# MCXN947_cm33_core0 register map
Vendor: nxp.com; File version: 1.0
CPU: CM33 r2p0, little endian, MPU, FPU, VTOR, 3 interrupt priority bits
Registers are 32-bit, read-write, reset 0x0 unless marked. A register's access mark holds for its fields unless they carry their own. Offsets are from the block's base; [hi:lo] are bit positions; lines under a group give offsets from that group; {n}, {i} and the like mark numbered series; 'fields as' and 'values as' point back to an identical list.

## INTM0 — INTM
Base 0x4005D000
0x00 INTM_MM — Monitor Mode
  [0] MM
    0=disable; 1=enable
0x04 INTM_IACK wo — Interrupt Acknowledge
  [9:0] IRQ — Interrupt Request
{0x8+0x10*i} mon[{i}] (i=0..3) group — Monitoring
  0x00 INTM_IRQSEL — Interrupt Request Select for Monitor mon_index
    [9:0] IRQ — Interrupt Request
  0x04 INTM_LATENCY — Interrupt Latency for Monitor mon_index
    [23:0] LAT — Latency
  0x08 INTM_TIMER — Timer for Monitor mon_index
    [23:0] TIMER
  0x0C INTM_STATUS ro — Status for Monitor mon_index
    [0] STATUS — Monitor status
      0=ST02 (Did not exceed); 1=ST01 (Exceeded)

## LP_FLEXCOMM0 — LP_FLEXCOMM
Base 0x40092000; alternate view of LPSPI0
Same registers: LP_FLEXCOMM1 0x40093000 (alternate view of LPSPI1), LP_FLEXCOMM2 0x40094000 (alternate view of LPSPI2), LP_FLEXCOMM3 0x40095000 (alternate view of LPSPI3), LP_FLEXCOMM4 0x400B4000 (alternate view of LPSPI4), LP_FLEXCOMM5 0x400B5000 (alternate view of LPSPI5), LP_FLEXCOMM6 0x400B6000 (alternate view of LPSPI6), LP_FLEXCOMM7 0x400B7000 (alternate view of LPSPI7), LP_FLEXCOMM8 0x400B8000 (alternate view of LPSPI8), LP_FLEXCOMM9 0x400B9000 (alternate view of LPSPI9)
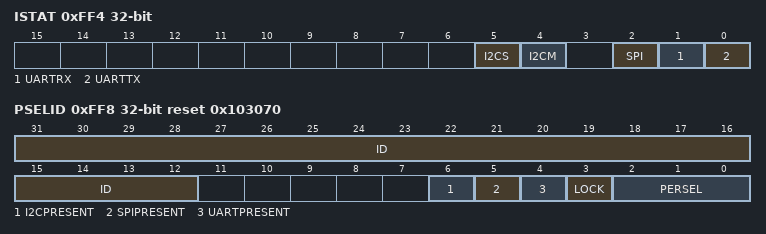
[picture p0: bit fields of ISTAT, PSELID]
0xFF4 ISTAT ro — Interrupt Status
  [all] fields
    0=CLR (Clear); 1=SET
  [5] I2CS — I2C Subordinate Interrupt
  [4] I2CM — I2C Controller Interrupt
  [2] SPI — SPI Interrupt
  [1] UARTRX — UART RX Interrupt
  [0] UARTTX — UART TX Interrupt
0xFF8 PSELID reset 0x103070 — Peripheral Select and ID
  [31:12] ID ro — LP_FLEXCOMM interface ID
  [6] I2CPRESENT ro
    0=FALSE (Not supported); 1=TRUE (Supported)
  [5] SPIPRESENT ro
    0=FALSE (Not supported); 1=TRUE (Supported)
  [4] UARTPRESENT ro
    0=FALSE (Not supported); 1=TRUE (Supported)
  [3] LOCK
    0=FALSE (PERSEL is writable); 1=TRUE (PERSEL is not writable)
  [2:0] PERSEL — Peripheral Select
    0=NONE (No peripheral selected); 1=UART; 2=SPI; 3=I2C; 7=UARTI2C (UART and I2C)

## SEMA42_0 — SEMA42
Base 0x400B1000
0x00 GATE3 8-bit — Gate
  [3:0] GTFSM — Gate Finite State Machine
    0=UNLOCKED (The gate is unlocked (free).); {v}=LOCKED_BY_D{v-1} (Domain {v-1} locked the gate.) (v=1..15)
0x01 GATE2 8-bit — Gate
  fields as GATE3
0x02 GATE1 8-bit — Gate
  fields as GATE3
0x03 GATE0 8-bit — Gate
  fields as GATE3
0x04 GATE7 8-bit — Gate
  fields as GATE3
0x05 GATE6 8-bit — Gate
  fields as GATE3
0x06 GATE5 8-bit — Gate
  fields as GATE3
0x07 GATE4 8-bit — Gate
  fields as GATE3
0x08 GATE11 8-bit — Gate
  fields as GATE3
0x09 GATE10 8-bit — Gate
  fields as GATE3
0x0A GATE9 8-bit — Gate
  fields as GATE3
0x0B GATE8 8-bit — Gate
  fields as GATE3
0x0C GATE15 8-bit — Gate
  fields as GATE3
0x0D GATE14 8-bit — Gate
  fields as GATE3
0x0E GATE13 8-bit — Gate
  fields as GATE3
0x0F GATE12 8-bit — Gate
  fields as GATE3
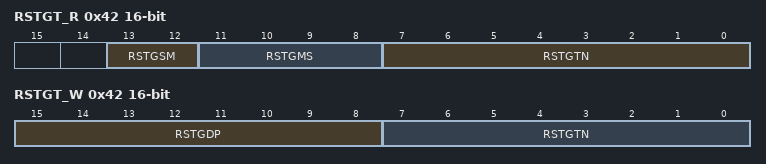
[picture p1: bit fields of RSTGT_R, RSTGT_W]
0x42 RSTGT_R 16-bit ro (RSTGT view) — Reset Gate Read
  [13:12] RSTGSM — Reset Gate Finite State Machine
    0=IDLE (Idle, waiting for the first data pattern write.); 1=WAITING (Waiting for the second data pattern write); 2=TWO_WRITE_DONE (The 2-write sequence has completed. Generate the specified gate reset(s). After the reset is performed, this machine returns to the idle (waiting for first data pattern write) state.)
  [11:8] RSTGMS — Reset Gate Domain
  [7:0] RSTGTN — Reset Gate Number
0x42 RSTGT_W 16-bit wo reset not defined (RSTGT view) — Reset Gate Write
  [15:8] RSTGDP — Reset Gate Data Pattern
  [7:0] RSTGTN — Reset Gate Number

## MAILBOX
Base 0x400B2000
{0x0+0x10*i} IRQ[{i}] (i=0..1) group
  0x00 IRQ — name (CPUn) Interrupt
    [31:0] INTREQ — Interrupt Request
  0x04 IRQSET wo reset not defined — name (CPUn) Interrupt Set
    [31:0] INTREQSET — Interrupt Request Set 0
  0x08 IRQCLR wo reset not defined — name (CPUn) Interrupt Clear
    [31:0] INTREQCLR — Interrupt Request Clear 0
0xF8 MUTEX reset 0x1 — Mutual Exclusion
  [0] EX — Mutual Exclusion Request
    0=UNAVAILABLE (Resource unavailable); 1=AVAILABLE (Resource available)
